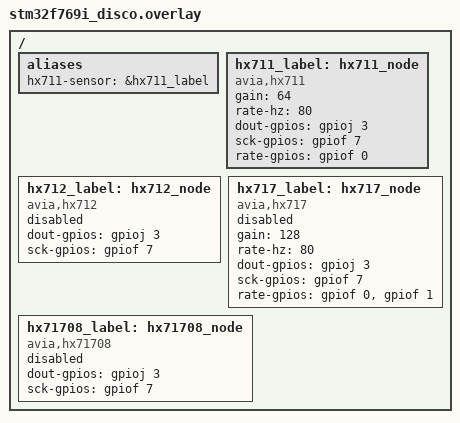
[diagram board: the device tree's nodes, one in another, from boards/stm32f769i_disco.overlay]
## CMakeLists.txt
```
# Copyright (c) 2020, George Gkinis
# SPDX-License-Identifier: Apache-2.0

cmake_minimum_required(VERSION 3.20.0)
find_package(Zephyr HINTS $ENV{ZEPHYR_BASE})
project(hx711)

FILE(GLOB app_sources src/*.c)
target_sources(app PRIVATE ${app_sources})
```

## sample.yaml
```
sample:
  name: HX711 24-Bit Analog-to-Digital Converter (ADC) for Weigh Scales
tests:
  sample.sensor.hx711:
    build_only: true
    tags: sensors
    depends_on: gpio
    filter: dt_compat_enabled("avia,hx711")
    platform_allow:
      - nrf52dk/nrf52832
      - stm32f769i_disco/stm32f769xx
```

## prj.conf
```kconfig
CONFIG_SENSOR=y
CONFIG_HX7XX=y
CONFIG_GPIO=y
CONFIG_LOG=y
CONFIG_REBOOT=y
CONFIG_PM=y
CONFIG_PM_DEVICE=y
CONFIG_PM_DEVICE_RUNTIME=n
CONFIG_CBPRINTF_FP_SUPPORT=y
```

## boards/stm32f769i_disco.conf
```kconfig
CONFIG_PM=n
```

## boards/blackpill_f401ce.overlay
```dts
/ {
    load_cell: hx711 {
        compatible = "avia,hx711";
        label = "HX711";
        sck-gpios = <&gpiob 12 GPIO_ACTIVE_HIGH>;
        dout-gpios = <&gpiob 13 GPIO_ACTIVE_HIGH>;
    };
};
```

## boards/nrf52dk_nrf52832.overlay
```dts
/*
 * Copyright (c) 2020 George Gkinis
 * SPDX-License-Identifier: Apache-2.0
 */

/ {
	aliases {
		hx711-sensor = &hx711;
	};

	hx711: hx711 {
		compatible = "avia,hx711";
		status = "okay";
		dout-gpios = <&gpio0 30 (GPIO_ACTIVE_HIGH | GPIO_PULL_UP)>;
		sck-gpios = <&gpio0 29 (GPIO_ACTIVE_HIGH | GPIO_PULL_UP)>;
		rate-gpios = <&gpio0 31 GPIO_ACTIVE_HIGH>;
	};
};
```

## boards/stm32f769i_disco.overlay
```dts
/*
 * Copyright (c) 2020 George Gkinis
 * SPDX-License-Identifier: Apache-2.0
 */

/ {
	aliases {
		hx711-sensor = &hx711_label;
	};

	hx711_label: hx711_node {
		compatible = "avia,hx711";
		gain = <64>;
		rate-hz = <80>;
		dout-gpios = <&gpioj 3 (GPIO_ACTIVE_HIGH | GPIO_PULL_UP)>;
		sck-gpios = <&gpiof 7 (GPIO_ACTIVE_HIGH | GPIO_PULL_UP)>;
		rate-gpios = <&gpiof 0 (GPIO_ACTIVE_HIGH | GPIO_PULL_UP)>;
	};

	hx712_label: hx712_node {
		compatible = "avia,hx712", "avia,hx710";
		status = "disabled";
		dout-gpios = <&gpioj 3 (GPIO_ACTIVE_HIGH | GPIO_PULL_UP)>;
		sck-gpios = <&gpiof 7 (GPIO_ACTIVE_HIGH | GPIO_PULL_UP)>;
	};

	hx717_label: hx717_node {
		compatible = "avia,hx717";
		status = "disabled";
		gain = <128>;
		rate-hz = <80>;
		dout-gpios = <&gpioj 3 (GPIO_ACTIVE_HIGH | GPIO_PULL_UP)>;
		sck-gpios = <&gpiof 7 (GPIO_ACTIVE_HIGH | GPIO_PULL_UP)>;
		rate-gpios = <&gpiof 0 (GPIO_ACTIVE_HIGH | GPIO_PULL_UP)>,
			     <&gpiof 1 (GPIO_ACTIVE_HIGH | GPIO_PULL_UP)>;
	};

	hx71708_label: hx71708_node {
		compatible = "avia,hx71708";
		status = "disabled";
		dout-gpios = <&gpioj 3 (GPIO_ACTIVE_HIGH | GPIO_PULL_UP)>;
		sck-gpios = <&gpiof 7 (GPIO_ACTIVE_HIGH | GPIO_PULL_UP)>;
	};
};
```

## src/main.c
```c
/*
 * Copyright (c) 2020 George Gkinis
 * SPDX-License-Identifier: Apache-2.0
 */

#include <stddef.h>

#include <zephyr/drivers/sensor.h>
#include <zephyr/drivers/sensor/hx7xx.h>
#include <zephyr/logging/log.h>

#define CALIBRATION_WEIGHT 500.0

LOG_MODULE_REGISTER(main, LOG_LEVEL_INF);

const struct device *hx711;

void set_rate(enum hx7xx_rate rate)
{
	static struct sensor_value rate_val;

	rate_val.val1 = rate;
	sensor_attr_set(hx711, SENSOR_CHAN_MASS, SENSOR_ATTR_SAMPLING_FREQUENCY, &rate_val);
}

void measure(void)
{
	static struct sensor_value weight;
	int ret;

	ret = sensor_sample_fetch(hx711);
	if (ret != 0) {
		LOG_ERR("Cannot take measurement: %d  ", ret);
	} else {
		sensor_channel_get(hx711, SENSOR_CHAN_MASS, &weight);
		LOG_INF("weight: %f", sensor_value_to_double(&weight));
	}
}

int main(void)
{
	hx711 = DEVICE_DT_GET(DT_ALIAS(hx711_sensor));

	__ASSERT(hx711 == NULL, "Failed to get device binding");

	if (!device_is_ready(hx711)) {
		LOG_ERR("Device is not ready");
		return -EBUSY;
	}

	LOG_INF("============= start =============");
	LOG_INF("device is %p, name is %s", hx711, hx711->name);

	LOG_INF("Calculating offset...");
	avia_hx7xx_tare(hx711, 15);

	LOG_INF("waiting for known weight of %f grams...", CALIBRATION_WEIGHT);

	for (int i = 5; i >= 0; i--) {
		LOG_INF(" %d..", i);
		k_msleep(1000);
	}

	LOG_INF("Calculating slope...");
	avia_hx7xx_calibrate(hx711, 15, CALIBRATION_WEIGHT);

	LOG_INF("== Test measure ==");
	while (true) {
		measure();
		k_msleep(1000);
	}

	return 0;
}
```
